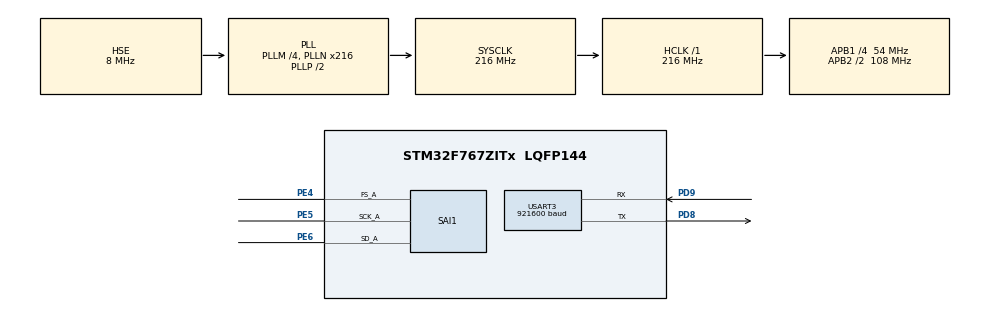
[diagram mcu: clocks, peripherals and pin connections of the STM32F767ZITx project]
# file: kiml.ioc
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CORTEX_M7.default_mode_Activation=1
Dma.Request0=SAI1_A
Dma.Request1=USART3_TX
Dma.SAI1_A.0.Direction=DMA_PERIPH_TO_MEMORY
Dma.SAI1_A.0.FIFOMode=DMA_FIFOMODE_DISABLE
Dma.SAI1_A.0.Instance=DMA2_Stream1
Dma.SAI1_A.0.MemDataAlignment=DMA_MDATAALIGN_WORD
Dma.SAI1_A.0.MemInc=DMA_MINC_ENABLE
Dma.SAI1_A.0.Mode=DMA_CIRCULAR
Dma.SAI1_A.0.PeriphDataAlignment=DMA_PDATAALIGN_WORD
Dma.SAI1_A.0.PeriphInc=DMA_PINC_DISABLE
Dma.SAI1_A.0.Priority=DMA_PRIORITY_HIGH
Dma.USART3_TX.1.Direction=DMA_MEMORY_TO_PERIPH
Dma.USART3_TX.1.FIFOMode=DMA_FIFOMODE_DISABLE
Dma.USART3_TX.1.Instance=DMA1_Stream3
Dma.USART3_TX.1.MemDataAlignment=DMA_MDATAALIGN_BYTE
Dma.USART3_TX.1.MemInc=DMA_MINC_ENABLE
Dma.USART3_TX.1.Mode=DMA_NORMAL
Dma.USART3_TX.1.PeriphDataAlignment=DMA_PDATAALIGN_BYTE
Dma.USART3_TX.1.PeriphInc=DMA_PINC_DISABLE
Dma.USART3_TX.1.Priority=DMA_PRIORITY_LOW
Mcu.Family=STM32F7
Mcu.Name=STM32F767ZITx
Mcu.Package=LQFP144
NVIC.DMA1_Stream3_IRQn=true\:0\:0\:false\:false\:true\:false\:true\:true
NVIC.DMA2_Stream1_IRQn=true\:0\:0\:false\:false\:true\:false\:true\:true
NVIC.PriorityGroup=NVIC_PRIORITYGROUP_4
NVIC.USART3_IRQn=true\:0\:0\:false\:false\:true\:true\:true\:true
PD8.Mode=Asynchronous
PD8.Signal=USART3_TX
PD9.Mode=Asynchronous
PD9.Signal=USART3_RX
PE4.Mode=SAI_A_Master
PE4.Signal=SAI1_FS_A
PE5.Mode=SAI_A_Master
PE5.Signal=SAI1_SCK_A
PE6.GPIO_PuPd=GPIO_PULLDOWN
PE6.Mode=SAI_A_Master
PE6.Signal=SAI1_SD_A
PH0/OSC_IN.Mode=HSE-External-Clock-Source
PH0/OSC_IN.Signal=RCC_OSC_IN
PH1/OSC_OUT.Mode=HSE-External-Clock-Source
PH1/OSC_OUT.Signal=RCC_OSC_OUT
ProjectManager.HeapSize=0x200
ProjectManager.StackSize=0x400
ProjectManager.TargetToolchain=STM32CubeIDE
RCC.AHBFreq_Value=216000000
RCC.APB1CLKDivider=RCC_HCLK_DIV4
RCC.APB1Freq_Value=54000000
RCC.APB1TimFreq_Value=108000000
RCC.APB2CLKDivider=RCC_HCLK_DIV2
RCC.APB2Freq_Value=108000000
RCC.APB2TimFreq_Value=216000000
RCC.CortexFreq_Value=216000000
RCC.HCLKFreq_Value=216000000
RCC.HSE_VALUE=8000000
RCC.HSI_VALUE=16000000
RCC.LSE_VALUE=32768
RCC.PLLM=4
RCC.PLLN=216
RCC.PLLSAIN=213
RCC.PLLSAIQ=13
RCC.PLLSAIQDiv=4
RCC.PLLSourceVirtual=RCC_PLLSOURCE_HSE
RCC.SYSCLKFreq_VALUE=216000000
RCC.SYSCLKSource=RCC_SYSCLKSOURCE_PLLCLK
RCC.USBFreq_Value=216000000
RCC.VCOOutputFreq_Value=432000000
SAI1.AudioFrequency-SAI_A_Master=SAI_AUDIO_FREQUENCY_16K
SAI1.AudioMode-SAI_A_Master=SAI_MODEMASTER_RX
SAI1.BasicDataSize-SAI_A_Master=SAI_PROTOCOL_DATASIZE_32BIT
SAI1.ErrorAudioFreq-SAI_A_Master=0.0 %
SAI1.InitProtocol-SAI_A_Master=Enable
SAI1.Instance-SAI_A_Master=SAI$Index_Block_A
SAI1.MClockEnable-SAI_A_Master=SAI_MASTERCLOCK_DISABLE
SAI1.RealAudioFreq-SAI_A_Master=16.0 KHz
SAI1.VirtualMode-SAI_A_Master=VM_MASTER
SAI1.VirtualProtocol-SAI_A_BASIC=VM_BASIC_PROTOCOL
USART3.BaudRate=921600
USART3.OverSampling=UART_OVERSAMPLING_8
USART3.VirtualMode-Asynchronous=VM_ASYNC
VP_SAI1_VP_$IpInstance_SAIA_SAI_BASIC.Mode=SAI_A_BASIC
board=custom

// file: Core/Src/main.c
/* USER CODE BEGIN Header */
/**
  ******************************************************************************
  * @file           : main.c
  * @brief          : Main program body
  ******************************************************************************
  * @attention
  *
  * Copyright (c) 2026 STMicroelectronics.
  * All rights reserved.
  *
  * This software is licensed under terms that can be found in the LICENSE file
  * in the root directory of this software component.
  * If no LICENSE file comes with this software, it is provided AS-IS.
  *
  ******************************************************************************
  */
/* USER CODE END Header */
#include "main.h"
#include "dma.h"
#include "sai.h"
#include "usart.h"
#include "gpio.h"

void SystemClock_Config(void);
static void MPU_Config(void);

int main(void)
{

  /* MPU Configuration--------------------------------------------------------*/
  MPU_Config();

  /* MCU Configuration--------------------------------------------------------*/

  /* Reset of all peripherals, Initializes the Flash interface and the Systick. */
  HAL_Init();

  /* Configure the system clock */
  SystemClock_Config();

  /* Initialize all configured peripherals */
  MX_GPIO_Init();
  MX_DMA_Init();
  MX_SAI1_Init();
  MX_USART3_UART_Init();

  /* Infinite loop */
  while (1)
  {

    /* USER CODE BEGIN 3 */
	  HAL_Delay(500);

  }
  /* USER CODE END 3 */
}

void SystemClock_Config(void)
{
  RCC_OscInitTypeDef RCC_OscInitStruct = {0};
  RCC_ClkInitTypeDef RCC_ClkInitStruct = {0};

  /** Configure the main internal regulator output voltage
  */
  __HAL_RCC_PWR_CLK_ENABLE();
  __HAL_PWR_VOLTAGESCALING_CONFIG(PWR_REGULATOR_VOLTAGE_SCALE1);

  /** Initializes the RCC Oscillators according to the specified parameters
  * in the RCC_OscInitTypeDef structure.
  */
  RCC_OscInitStruct.OscillatorType = RCC_OSCILLATORTYPE_HSE;
  RCC_OscInitStruct.HSEState = RCC_HSE_BYPASS;
  RCC_OscInitStruct.PLL.PLLState = RCC_PLL_ON;
  RCC_OscInitStruct.PLL.PLLSource = RCC_PLLSOURCE_HSE;
  RCC_OscInitStruct.PLL.PLLM = 4;
  RCC_OscInitStruct.PLL.PLLN = 216;
  RCC_OscInitStruct.PLL.PLLP = RCC_PLLP_DIV2;
  RCC_OscInitStruct.PLL.PLLQ = 2;
  RCC_OscInitStruct.PLL.PLLR = 2;
  if (HAL_RCC_OscConfig(&RCC_OscInitStruct) != HAL_OK)
  {
    Error_Handler();
  }

  /** Activate the Over-Drive mode
  */
  if (HAL_PWREx_EnableOverDrive() != HAL_OK)
  {
    Error_Handler();
  }

  /** Initializes the CPU, AHB and APB buses clocks
  */
  RCC_ClkInitStruct.ClockType = RCC_CLOCKTYPE_HCLK|RCC_CLOCKTYPE_SYSCLK
                              |RCC_CLOCKTYPE_PCLK1|RCC_CLOCKTYPE_PCLK2;
  RCC_ClkInitStruct.SYSCLKSource = RCC_SYSCLKSOURCE_PLLCLK;
  RCC_ClkInitStruct.AHBCLKDivider = RCC_SYSCLK_DIV1;
  RCC_ClkInitStruct.APB1CLKDivider = RCC_HCLK_DIV4;
  RCC_ClkInitStruct.APB2CLKDivider = RCC_HCLK_DIV2;

  if (HAL_RCC_ClockConfig(&RCC_ClkInitStruct, FLASH_LATENCY_7) != HAL_OK)
  {
    Error_Handler();
  }
}

 /* MPU Configuration */

void MPU_Config(void)
{
  MPU_Region_InitTypeDef MPU_InitStruct = {0};

  /* Disables the MPU */
  HAL_MPU_Disable();

  /** Initializes and configures the Region and the memory to be protected
  */
  MPU_InitStruct.Enable = MPU_REGION_ENABLE;
  MPU_InitStruct.Number = MPU_REGION_NUMBER0;
  MPU_InitStruct.BaseAddress = 0x0;
  MPU_InitStruct.Size = MPU_REGION_SIZE_4GB;
  MPU_InitStruct.SubRegionDisable = 0x87;
  MPU_InitStruct.TypeExtField = MPU_TEX_LEVEL0;
  MPU_InitStruct.AccessPermission = MPU_REGION_NO_ACCESS;
  MPU_InitStruct.DisableExec = MPU_INSTRUCTION_ACCESS_DISABLE;
  MPU_InitStruct.IsShareable = MPU_ACCESS_SHAREABLE;
  MPU_InitStruct.IsCacheable = MPU_ACCESS_NOT_CACHEABLE;
  MPU_InitStruct.IsBufferable = MPU_ACCESS_NOT_BUFFERABLE;

  HAL_MPU_ConfigRegion(&MPU_InitStruct);
  /* Enables the MPU */
  HAL_MPU_Enable(MPU_PRIVILEGED_DEFAULT);

}

void Error_Handler(void)
{
  __disable_irq();
  while (1)
  {
  }
}
